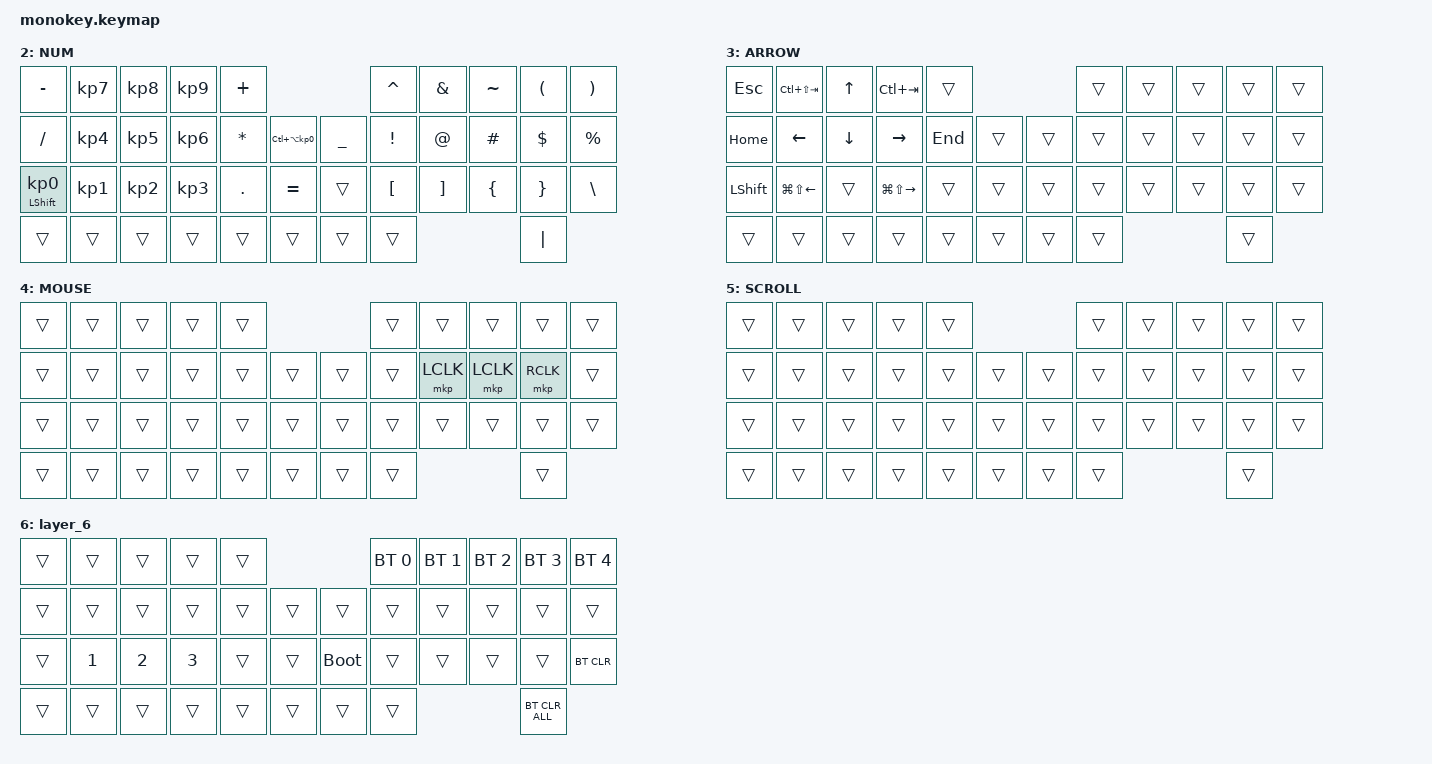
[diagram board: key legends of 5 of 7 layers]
#include <behaviors.dtsi>
#include <dt-bindings/zmk/bt.h>
#include <dt-bindings/zmk/keys.h>
#include <behaviors/auto_layer.dtsi>
#include <dt-bindings/zmk/pointing.h>
#include <dt-bindings/zmk/mouse.h>

#define MOUSE 4
#define SCROLL 5
#define NUM 6

&mt {
    flavor = "balanced";
    quick-tap-ms = <0>;
};

/ {
    chosen {
        zmk,rgbled-widget = &led_strip;
    };

    combos {
        compatible = "zmk,combos";
        tab { bindings = <&kp TAB>; key-positions = <11 12>; };
        shift_tab { bindings = <&kp LS(TAB)>; key-positions = <12 13>; };
        muhennkann { bindings = <&to_layer_0 INT_MUHENKAN>; key-positions = <11 10>; };
        double_quotation { bindings = <&kp DOUBLE_QUOTES>; key-positions = <20 21>; };
    };

    macros {
        to_layer_0: to_layer_0 {
            compatible = "zmk,behavior-macro-one-param";
            #binding-cells = <1>;
            bindings = <&to 0 &macro_param_1to1 &kp MACRO_PLACEHOLDER>;
            label = "TO_LAYER_0";
        };
        macro_repeated_backspace: macro_repeated_backspace {
            compatible = "zmk,behavior-macro";
            label = "MACRO_REPEATED_BACKSPACE";
            #binding-cells = <0>;
            bindings = <&macro_repeat_press &kp BACKSPACE>;
        };
    };

    tap_dance {
        compatible = "zmk,tap-dance";
        td_backspace {
            label = "TD_BACKSPACE";
            taps = <1>, <2>;
            bindings = <&kp BACKSPACE, &macro_repeated_backspace>;
        };
    };

    behaviors {
        right_click: right_click_behavior {
            compatible = "zmk,behavior-mouse-key";
            label = "RIGHT_CLICK";
            #binding-cells = <0>;
            bindings = <&mkp MB2>;
        };
        backspace_hold_layer: backspace_hold_layer {
            compatible = "zmk,behavior-hold-tap";
            label = "BACKSPACE_HOLD_LAYER";
            bindings = < &kp BACKSPACE >, < &mo 3 >;
            tapping-term-ms = <200>;
        };
    };

    &auto_layer {
        continue-list = <MB1 MB2 MB3 BT_CLR BT_SEL 0 BT_SEL 1 BT_SEL 2 BT_SEL 3 BT_SEL 4>;
    };

    keymap {
        compatible = "zmk,keymap";

        default_layer {
            bindings = <
&kp Q      &kp W           &kp E         &kp R           &kp T                                &kp Y          &kp U                &kp I     &kp O     &kp P
&kp A      &kp S           &kp D         &kp F           &kp G                                &kp H          &kp J                &kp K     &kp L     &kp ENTER
&kp Z      &kp X           &kp C         &kp V           &kp B                                &kp N          &kp M                &mkp MB1  &mkp MB2  &kp SLASH
&kp LCTRL  &kp LEFT_SHIFT  &kp LEFT_ALT  &kp LEFT_COMMAND  &lt 1 SPACE  &to_layer_0 2 TAB    &kp BACKSPACE  &lt 3 RIGHT_COMMAND            &kp ESC   &kp ESC
            >;
            sensor-bindings = <&inc_dec_kp PG_UP PAGE_DOWN>;
        };

        FUNCTION {
            bindings = <
&trans  &trans  &trans  &trans  &trans                    &kp F1  &kp F2  &kp F3  &kp F4  &kp F5
&trans  &trans  &trans  &trans  &trans            &trans  &kp F6  &kp F7  &kp F8  &kp F9  &kp F10
&trans  &trans  &trans  &trans  &trans            &trans  &kp F11 &trans  &trans  &trans  &trans
&trans  &trans  &trans  &trans  &trans  &trans    &trans  &trans                  &kp ESC &kp F12
            >;
        };

        NUM {
            bindings = <
&kp MINUS                    &kp KP_NUMBER_7  &kp KP_NUMBER_8  &kp KP_NUMBER_9  &kp PLUS                                                   &kp CARET          &kp AMPERSAND      &kp TILDE       &kp LEFT_PARENTHESIS  &kp RIGHT_PARENTHESIS
&kp SLASH                    &kp KP_NUMBER_4  &kp KP_NUMBER_5  &kp KP_NUMBER_6  &kp ASTERISK  &kp LC(LA(KP_NUMBER_0))    &kp UNDERSCORE  &kp EXCLAMATION    &kp AT_SIGN        &kp HASH        &kp DOLLAR            &kp PERCENT
&mt LEFT_SHIFT KP_NUMBER_0  &kp KP_NUMBER_1  &kp KP_NUMBER_2  &kp KP_NUMBER_3  &kp PERIOD    &kp EQUAL                  &trans          &kp LEFT_BRACKET   &kp RIGHT_BRACKET  &kp LEFT_BRACE  &kp RIGHT_BRACE       &kp BACKSLASH
&trans                       &trans           &trans           &trans           &trans        &trans                     &trans          &trans                                                &kp PIPE
            >;
        };

        ARROW {
            bindings = <
&kp ESCAPE      &kp LC(LS(TAB))         &kp UP_ARROW    &kp LC(TAB)              &trans                     &trans  &trans  &trans  &trans  &trans
&kp HOME        &kp LEFT_ARROW          &kp DOWN_ARROW  &kp RIGHT_ARROW          &kp END  &trans    &trans  &trans  &trans  &trans  &trans  &trans
&kp LEFT_SHIFT  &kp LG(LS(LEFT_ARROW))  &trans          &kp LG(LS(RIGHT_ARROW))  &trans   &trans    &trans  &trans  &trans  &trans  &trans  &trans
&trans          &trans                  &trans          &trans                   &trans   &trans    &trans  &trans                          &trans
            >;
            sensor-bindings = <&inc_dec_kp LC(PAGE_UP) LC(PAGE_DOWN)>;
        };

        MOUSE {
            bindings = <
&trans  &trans  &trans  &trans  &trans                    &trans  &trans  &trans     &trans     &trans
&trans  &trans  &trans  &trans  &trans  &trans    &trans  &trans  &mkp LCLK  &mkp LCLK  &mkp RCLK  &trans
/* 右手人差し指(J)から順に： (J:左)  (K:左)     (L:右)  */
&trans  &trans  &trans  &trans  &trans  &trans    &trans  &trans  &trans     &trans     &trans     &trans
&trans  &trans  &trans  &trans  &trans  &trans    &trans  &trans                                &trans
            >;
        };

        SCROLL {
            bindings = <
&trans  &trans  &trans  &trans  &trans                    &trans  &trans  &trans  &trans  &trans
&trans  &trans  &trans  &trans  &trans  &trans    &trans  &trans  &trans  &trans  &trans  &trans
&trans  &trans  &trans  &trans  &trans  &trans    &trans  &trans  &trans  &trans  &trans  &trans
&trans  &trans  &trans  &trans  &trans  &trans    &trans  &trans                          &trans
            >;
        };

        layer_6 {
            bindings = <
&trans  &trans        &trans        &trans        &trans                         &bt BT_SEL 0  &bt BT_SEL 1  &bt BT_SEL 2  &bt BT_SEL 3  &bt BT_SEL 4
&trans  &trans        &trans        &trans        &trans  &trans    &trans       &trans        &trans        &trans        &trans        &trans
&trans  &kp NUMBER_1  &kp NUMBER_2  &kp NUMBER_3  &trans  &trans    &bootloader  &trans        &trans        &trans        &trans        &bt BT_CLR
&trans  &trans        &trans        &trans        &trans  &trans    &trans       &trans                                                  &bt BT_CLR_ALL
            >;
        };
    };
};

/* LEDウィジェットの色設定 */
&led_strip {
    layers = <
        0   0   0    /* 0: Off */
        255 255 255  /* 1: FUNCTION */
        255 255 255  /* 2: NUM */
        255 255 255  /* 3: ARROW */
        0   0   255  /* 4: MOUSE (Blue) */
        0   255 0    /* 5: SCROLL (Green) */
        255 0   0    /* 6: layer_6 (Red) */
    >;
};

/* 🌟 工程3: トラックボール連動設定（overlay側と同期） */
&trackball_peripheral_listener {
    status = "okay";
    /* input-processors は overlay 側で定義済みですが、二重定義でも問題ありません */
    input-processors = <&zip_auto_layer MOUSE 1000>;
};
